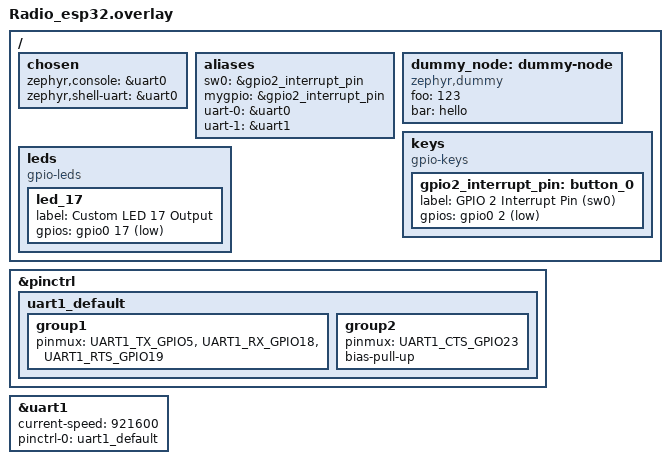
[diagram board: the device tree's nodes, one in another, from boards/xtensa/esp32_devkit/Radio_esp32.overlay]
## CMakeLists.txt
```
cmake_minimum_required(VERSION 3.20.0)

set(BOARD esp32_devkitc/esp32/procpu)
set(DTC_OVERLAY_FILE boards/espressif/esp32_devkitc/Radio.overlay)

# set(ZEPHYR_RADIOUART_CMAKE_DIR ${CMAKE_CURRENT_LIST_DIR}/drivers/uartone)
# set(ZEPHYR_RADIOUART_KCONFIG   ${CMAKE_CURRENT_LIST_DIR}/drivers/uartone)
# 

list(APPEND ZEPHYR_EXTRA_MODULES

${CMAKE_CURRENT_SOURCE_DIR}/drivers/uartone 
# ${CMAKE_CURRENT_SOURCE_DIR}/drivers/itwoc

)


find_package(Zephyr REQUIRED HINTS $ENV{ZEPHYR_BASE})
project(uart_manual_driver)

set(CMAKE_CXX_STANDARD 14)
set(CMAKE_CXX_STANDARD_REQUIRED ON)



target_sources(app  PRIVATE
    src/Radio.cpp

)
```

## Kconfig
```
mainmenu "Radio Kconfig configuration"

    rsource "drivers/Kconfig"
    source  "Kconfig.zephyr"
```

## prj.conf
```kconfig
# Logging

# Bluetooth

# Wi-Fi

# 802.15.4 (for UWB transceiver drivers)



CONFIG_SERIAL=y
CONFIG_CONSOLE=y
CONFIG_UART_CONSOLE=y
CONFIG_LOG=y
CONFIG_GPIO=y
# CONFIG_I2C=y



# Enable C++ Support
CONFIG_CPP=y
CONFIG_STD_CPP17=y
# CONFIG_LIB_CPLUSPLUS=y

# Enable C++ Runtime Features
CONFIG_CPP_EXCEPTIONS=n
CONFIG_CPP_RTTI=n
CONFIG_I2C=y

CONFIG_LOG_DEFAULT_LEVEL=3
CONFIG_LOG_BACKEND_SHOW_COLOR=n



# Use full C++ standard library /for srl  containers


# Use Newlib as the C library (required for full C++ features)
CONFIG_NEWLIB_LIBC=y
CONFIG_REQUIRES_FULL_LIBCPP=y
# CONFIG_MCUBOOT_UPDATE_FOOTER_SIZE=0x30




#mcu  mgr for OTA 
# CONFIG_MCUMGR=y

CONFIG_BOOTLOADER_MCUBOOT=y


#modem subsys
CONFIG_MODEM_MODULES=y
CONFIG_MODEM_PIPE=y

#enabling the backend dastsctures  for the data to be collected
CONFIG_MODEM_BACKEND_UART=y
# CONFIG_UART_INTERRUPT_DRIVEN=y

# Helper Modules
CONFIG_MODEM_CHAT=y
CONFIG_MODEM_DEDICATED_WORKQUEUE=y
CONFIG_MODEM_DEDICATED_WORKQUEUE_STACK_SIZE=2048
```

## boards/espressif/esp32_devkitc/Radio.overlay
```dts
/ {
  

chosen{

    zephyr,console = &uart0;
    zephyr,shell-uart = &uart0;
    zephyr,flash-controller =  &flash;
    zephyr,flash = &flash0;
    zephhyr,code-partition = &slot0_partition;

};
aliases{

    serial1 = &uart0;
    modem = &uart1;
};

};
//alias 

&uart1{
status=  "okay";
current-speed = <115200>;
pinctrl-0 = <&uart1_default>;
pinctrl-names = "default";
};

&pinctrl{

uart1_default: uart1_default {

group1{

    pinmux = <UART1_TX_GPIO17>,
    <UART1_RX_GPIO16>;  
};

};

};
```

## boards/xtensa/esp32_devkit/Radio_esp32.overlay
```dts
/{
    #address-cells = <1>;
    #size-cells = <1>;
    
    
    chosen {
        zephyr,console = &uart0;
        zephyr,shell-uart = &uart0;
    };

    
    aliases {
        
        sw0 = &gpio2_interrupt_pin; 
        mygpio = &gpio2_interrupt_pin;

        
        uart-0 = &uart0;
        uart-1 = &uart1;
    };

    
    dummy_node: dummy-node {
        compatible = "zephyr,dummy";
        status = "okay";
        foo = <123>;
        bar = "hello";
    };
    
    
    keys: keys {
        compatible = "gpio-keys";        
        
        gpio2_interrupt_pin: button_0 {
            label = "GPIO 2 Interrupt Pin (sw0)";
            
            gpios = <&gpio0 2 (GPIO_PULL_UP | GPIO_ACTIVE_LOW)>;
        };
    };
    
    
    
    leds: leds {
        compatible = "gpio-leds";

        
        led_17: led_17 {
            label = "Custom LED 17 Output";
            
            
            
            gpios = <&gpio0 17 GPIO_ACTIVE_LOW>; 
        };
    };
};

&pinctrl {
    uart1_default: uart1_default {
        group1 {
            pinmux = <UART1_TX_GPIO5>,
                     <UART1_RX_GPIO18>,
                     <UART1_RTS_GPIO19>;
        };
        group2 {
            pinmux = <UART1_CTS_GPIO23>;
            bias-pull-up;
        };
    };
};

&uart1 {
    status = "okay";
    current-speed = <921600>;
    pinctrl-0 = <&uart1_default>;
    pinctrl-names = "default";
};
```

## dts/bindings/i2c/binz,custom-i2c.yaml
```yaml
description: Custom I2C Controller Binding for ESP32 by Binz Vendor
compatible: "binz,custom-i2c"
include: [i2c-controller.yaml ,  base.yaml ] 

properties:
  reg:
    required: true
  clock-frequency:
    type: int
    default: 100000
    description: "I2C clock frequency in Hz."
  sda-gpios:
    type: phandle-array
    required: true
  scl-gpios:
    type: phandle-array
    required: true
```

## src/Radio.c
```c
    #include <zephyr/kernel.h>
    #include <zephyr/logging/log.h>
    #include <zephyr/drivers/gpio.h>
    #include <errno.h>
	#include  <threads.h>
    #include <zephyr/sys/printk.h> // Include printk for the main loop




	
    LOG_MODULE_REGISTER(radio, LOG_LEVEL_DBG);


    int main(void)
    {

		

        // Your main thread loop
        while (1) {
            printk("in the main loop\n");
            k_msleep(1000);
        }
    }
```

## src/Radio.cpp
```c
#include <zephyr/kernel.h>
#include <zephyr/device.h>
#include <zephyr/devicetree.h>
#include <zephyr/drivers/uart.h>
#include <zephyr/logging/log.h>
#include <zephyr/modem/backend/uart.h>
#include <zephyr/modem/backend/tty.h>

#include <zephyr/modem/pipe.h>




#ifdef  CONFIG_RADIO_UART_INSTANCE
#include "uartone.hpp"

#endif // DEBUG
static uint8_t uart_backend_receive_buf[512];

static uint8_t uart_backend_transmit_buf[512];



#ifdef CONFIG_BINZ_ITWOC
#include "Binzitwoc.hpp"
#define I2C_CONTROLLER_NODE DT_NODELABEL(i2c0_binz)
static const struct device *i2c0_dev = DEVICE_DT_GET(I2C_CONTROLLER_NODE);
#endif // DEBUG
LOG_MODULE_REGISTER(main, CONFIG_LOG_DEFAULT_LEVEL);
static struct modem_backend_uart uart_backend;
static struct  modem_pipe *modem_pipe;

#define  UART_DEVICE  DT_NODELABEL(uart1)
//OUR  UART mdoem cumminication
const struct device *uart_modem_dev = DEVICE_DT_GET(UART_DEVICE); 

#ifdef  MODEM_BACKEND_UART
#endif // MODEM_BACKEND_UART


/*
//notes here
modem_backend_uart has modem_pipe which acts a standard connector 
for various high-level to low-level communication.
modem_pipe inturn  has a pointer member  of  modem_pipe_api(that handles the
open,close receive, transmit of data).

*/
const static struct modem_backend_uart_config uart_modem_config ={

.uart = uart_modem_dev,
.receive_buf = uart_backend_receive_buf,

.receive_buf_size =sizeof( uart_backend_receive_buf),
.transmit_buf = uart_backend_transmit_buf,
.transmit_buf_size = sizeof(uart_backend_transmit_buf),



};



#ifdef __cplusplus__
 extern "C" {
#endif


const char* i2c_data= "Data fro mbinz itwoc driver\n";

int main(void)
{
  

if(!device_is_ready(uart_modem_dev)) {

LOG_ERR("Uart mdoem dev is not ready");
return -ENODEV;

}   



modem_pipe = modem_backend_uart_init(&uart_backend, &uart_modem_config);



    while (true) {
    printk("welcome to the OTA %d \n",k_uptime_get_32());
        k_msleep(1000);
    }
    return 0;
}


#ifdef __cplusplus__

 }
#endif
```
